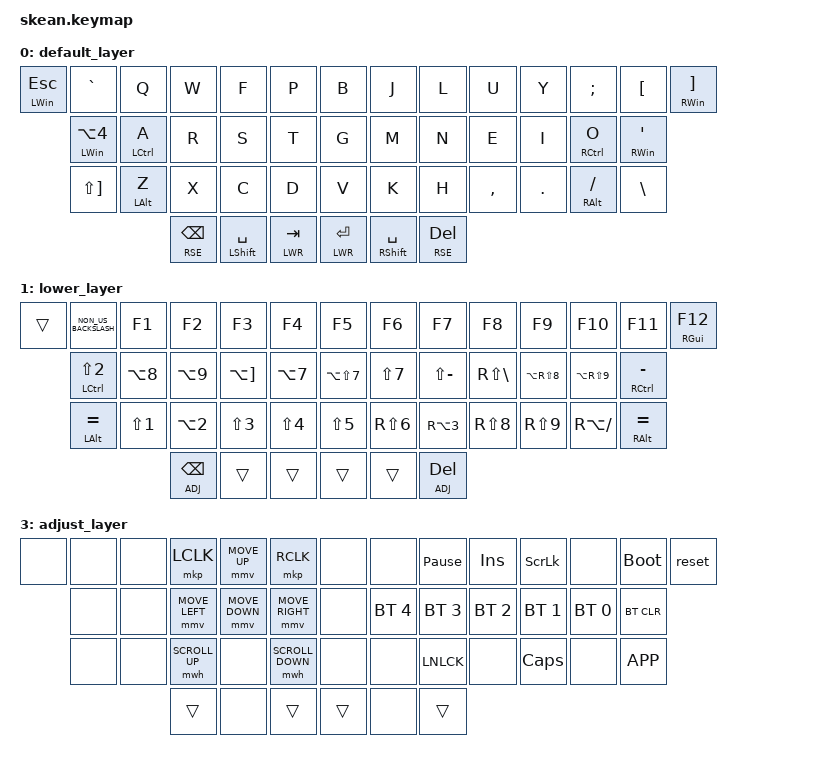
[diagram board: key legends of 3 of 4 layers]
/*
 * Copyright (c) 2020 The ZMK Contributors
 *
 * SPDX-License-Identifier: MIT
 */

#include <behaviors.dtsi>
#include <dt-bindings/zmk/keys.h>
#include <dt-bindings/zmk/bt.h>
#include <dt-bindings/zmk/mouse.h>

#define DEF 0
#define LWR 1
#define RSE 2
#define ADJ 3

&lt {
	flavor = "tap-preferred";
	tapping-term-ms = <200>;
};
&mt { 
	flavor = "tap-preferred";
	tapping-term-ms = <200>;
};

#define U_MOUSE_MOVE_MAX 1500
#undef MOVE_UP
#undef MOVE_DOWN
#undef MOVE_LEFT
#undef MOVE_RIGHT
#define MOVE_UP MOVE_VERT(-U_MOUSE_MOVE_MAX)
#define MOVE_DOWN MOVE_VERT(U_MOUSE_MOVE_MAX)
#define MOVE_LEFT MOVE_HOR(-U_MOUSE_MOVE_MAX)
#define MOVE_RIGHT MOVE_HOR(U_MOUSE_MOVE_MAX)

&mmv {
	time-to-max-speed-ms = <400>;
};

#define U_MOUSE_SCROLL_MAX 50

#undef SCROLL_UP
#undef SCROLL_DOWN
#undef SCROLL_LEFT
#undef SCROLL_RIGHT
#define SCROLL_UP SCROLL_VERT(U_MOUSE_SCROLL_MAX)
#define SCROLL_DOWN SCROLL_VERT(-U_MOUSE_SCROLL_MAX)
#define SCROLL_LEFT SCROLL_HOR(-U_MOUSE_SCROLL_MAX)
#define SCROLL_RIGHT SCROLL_HOR(U_MOUSE_SCROLL_MAX)

&mwh {
	  time-to-max-speed-ms = <750>;                 /* <--- How long time until max speed is reached */
};
/ {
        keymap {
                compatible = "zmk,keymap";

                default_layer {
// -----------------------------------------------------------------------------------------
// |  GUI/ESC |   <    |  Q  |  W  |  E  |  P  |  G  |   |  J  |  L   |  U  |  Y  |  Ö  |  Å     | GUI/¨ |
//            | CTRL/$ |  A  |  R  |  S  |  T  |  D  |   |  H  |  N   |  E  |  I  |  O  | CTRL/Ä |
//            | LALT/@ |  Z  |  X  |  C  |  V  |  B  |   |  K  |  M   |  ,  |  .  |  -  | RALT/' |
//                     |RSE/BSPC | SFHT/SPC | LWR/TAB|   | LWR/ENT | SFHT/SPC | RSE/DEL |
                        bindings = <
   &mt LWIN ESC &kp GRAVE	&kp Q &kp W &kp F &kp P &kp B         &kp J &kp L &kp U     &kp Y   &kp SEMI &kp LBKT &mt RWIN RBKT
            &mt LWIN LA(N4) 	&mt LCTRL A &kp R &kp S &kp T &kp G         &kp M &kp N &kp E     &kp I   &mt RCTRL O    &mt RWIN SQT
            &kp LS(RBKT)	&mt LALT Z &kp X &kp C &kp D &kp V         &kp K &kp H &kp COMMA &kp DOT &mt RALT FSLH &kp BSLH
		&lt RSE BSPC &mt LSHFT SPACE &lt LWR TAB		&lt LWR RET &mt RSHFT SPACE &lt RSE DEL
                        >;
                };

                lower_layer {
// -----------------------------------------------------------------------------------------
// | GUI/ESC |  §       |  F1 |  F2 |  F3 |  F4 |  F5 |   |  F6 |  F7 |  F8 |  F9 | F10 | F11    | GUI/F12 |
//           |  CTRL/{  |  [  |  ]  |  }  |  |  |  \  |   |  /  |  ?  |  *  |  (  |  )  | CTRL/+ |
//           |  ALT/´   |  1  |  2  |  3  |  4  |  5  |   |  6  |  7  |  8  |  9  |  0  | ALT/`  |
//                    | ADJ/BSPC | SHFT/SPC | LWR/TAB |   | LWR/ENT | SHFT/SPC | ADJ/DEL|
                        bindings = <
   &trans &kp NON_US_BACKSLASH &kp F1     &kp F2     &kp F3         &kp F4     &kp F5           &kp F6	   &kp F7        &kp F8       &kp F9     &kp F10      &kp F11            &mt RGUI F12
          &mt LCTRL LS(N2) &kp LA(N8) &kp LA(N9) &kp LA(RBKT) &kp LA(N7) &kp LA(LS(N7))		&kp LS(N7) &kp LS(MINUS) &kp RS(BSLH) &kp LA(RS(N8)) &kp LA(RS(N9))   &mt RCTRL MINUS
          &mt LALT EQUAL       &kp LS(N1) &kp LA(N2) &kp LS(N3)     &kp LS(N4) &kp LS(N5)       &kp RS(N6) &kp RA(N3)    &kp RS(N8)   &kp RS(N9) &kp RA(FSLH) &mt RALT EQUAL
                                              &lt ADJ BSPC &trans &trans   			&trans &trans &lt ADJ DEL
                        >;
                };

                raise_layer {
// -----------------------------------------------------------------------------------------
// | GUI/ESC | ESC    |  /  |  7  |  8  |  9  |  -  |   | VOLU | HOME | PRSC | PGUP | CUT   | S-CPY  | GUI/~ |
//           | CTRL/= |  *  |  4  |  5  |  6  |  +  |   | MUT  | LEFT |  UP  | RGHT | PASTE | CTRL/" |
//           | ALT/.  |  0  |  1  |  2  |  3  |  ,  |   | VOLD | END  | DOWN | PGDN | COPY  | ALT/`  |
//                  | ADJ/BSPC | SFHT/SPC | LWR/TAB |   | LWR/ENT | SHFT/SPC | ADJ/DEL |
                        bindings = <
   &trans &kp ESC	     &kp KP_SLASH    &kp N7 &kp N8 &kp N9 &kp KP_MINUS	  	&kp C_VOL_UP &kp HOME &kp UP	&kp PG_UP &kp RG(X) &kp RA(RS(RG(V))) &mt RCMD LA(RBKT)
          &mt LCTRL KP_EQUAL &kp KP_MULTIPLY &kp N4 &kp N5 &kp N6 &kp KP_PLUS		&kp C_MUTE   &kp LEFT &kp DOWN  &kp RIGHT &kp RG(C) &mt RCTRL LS(N2)
          &mt LALT DOT       &kp N0          &kp N1 &kp N2 &kp N3 &kp KP_DOT		&kp C_VOL_DN &kp END  &kp PSCRN &kp PG_DN &kp RG(V) &mt RALT RS(EQUAL)
                                                           &trans &trans &lt ADJ RET   	&lt ADJ ESC &trans &trans
                        >;
                };
                adjust_layer {
// -----------------------------------------------------------------------------------------
// |     |     |     | MOUSE LCLK | MOUSE UP  | MOUSE RCLK |     |   |     | BREAK | INS | SLCK |     | BLDR  | RST |
//       |     |     | MOUSE LEFT | MOUSE DWN | MOUSE RGHT |     |   | BT4 | BT3   | BT2 | BT1  | BT0 | BTCLR |
//       |     |     | MWHEEL UP  |	      | MWHEEL DWN |     |   |     | NLCK  |     | CLCK |     | APP   |
//                  		  | ADJ/BSPC  |  | LWR/TAB |	 | LWR/ENT |  | ADJ/SPC |
                        bindings = <
   &none &none  &none &mkp LCLK      &mmv MOVE_UP   &mkp RCLK        &none        	&none        &kp PAUSE_BREAK    &kp INS      &kp SLCK     &none         &bootloader &reset
         &none	&none &mmv MOVE_LEFT &mmv MOVE_DOWN &mmv MOVE_RIGHT  &none       	&bt BT_SEL 4 &bt BT_SEL 3 	&bt BT_SEL 2 &bt BT_SEL 1 &bt BT_SEL 0  &bt BT_CLR
         &none  &none &mwh SCROLL_UP &none          &mwh SCROLL_DOWN &none         	&none        &kp LNLCK        	&none        &kp CAPS     &none         &kp K_APP
                                                                    &trans &none &trans   &trans &none &trans
                        >;
                };
        };
};

/* vim: set nowrap: */
